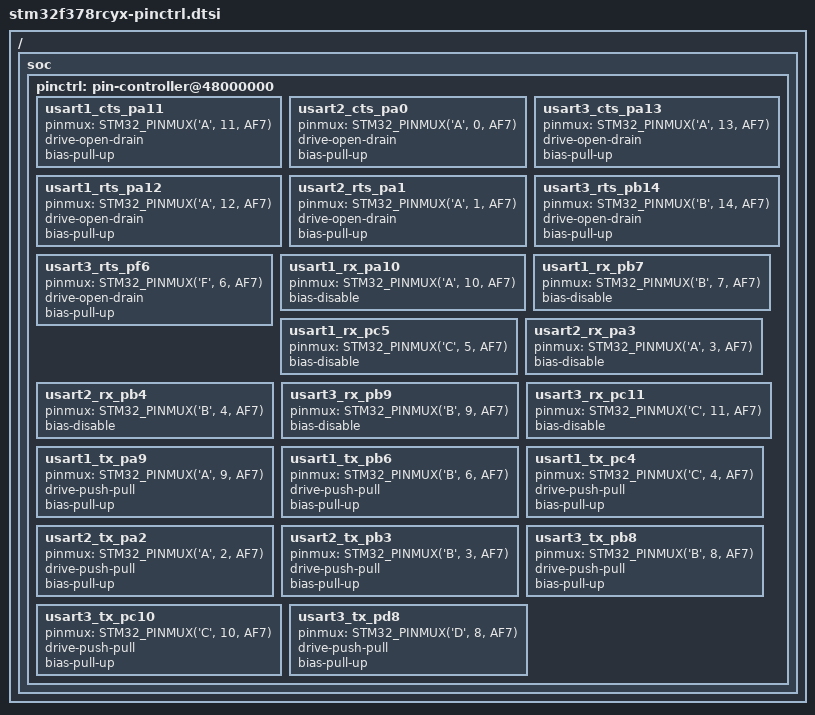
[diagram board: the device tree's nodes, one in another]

/*
 * NOTE: Autogenerated file using stm32_pinctrl_gen.py
 *
 * SPDX-License-Identifier: Apache-2.0
 */

#include <dt-bindings/pinctrl/stm32-pinctrl.h>

/ {
	soc {
		pinctrl: pin-controller@48000000 {
			/* UART_CTS */
			usart1_cts_pa11: usart1_cts_pa11 {
				pinmux = <STM32_PINMUX('A', 11, AF7)>;
				drive-open-drain;
				bias-pull-up;
			};

			usart2_cts_pa0: usart2_cts_pa0 {
				pinmux = <STM32_PINMUX('A', 0, AF7)>;
				drive-open-drain;
				bias-pull-up;
			};

			usart3_cts_pa13: usart3_cts_pa13 {
				pinmux = <STM32_PINMUX('A', 13, AF7)>;
				drive-open-drain;
				bias-pull-up;
			};


			/* UART_RTS */
			usart1_rts_pa12: usart1_rts_pa12 {
				pinmux = <STM32_PINMUX('A', 12, AF7)>;
				drive-open-drain;
				bias-pull-up;
			};

			usart2_rts_pa1: usart2_rts_pa1 {
				pinmux = <STM32_PINMUX('A', 1, AF7)>;
				drive-open-drain;
				bias-pull-up;
			};

			usart3_rts_pb14: usart3_rts_pb14 {
				pinmux = <STM32_PINMUX('B', 14, AF7)>;
				drive-open-drain;
				bias-pull-up;
			};

			usart3_rts_pf6: usart3_rts_pf6 {
				pinmux = <STM32_PINMUX('F', 6, AF7)>;
				drive-open-drain;
				bias-pull-up;
			};


			/* UART_RX */
			usart1_rx_pa10: usart1_rx_pa10 {
				pinmux = <STM32_PINMUX('A', 10, AF7)>;
				bias-disable;
			};

			usart1_rx_pb7: usart1_rx_pb7 {
				pinmux = <STM32_PINMUX('B', 7, AF7)>;
				bias-disable;
			};

			usart1_rx_pc5: usart1_rx_pc5 {
				pinmux = <STM32_PINMUX('C', 5, AF7)>;
				bias-disable;
			};

			usart2_rx_pa3: usart2_rx_pa3 {
				pinmux = <STM32_PINMUX('A', 3, AF7)>;
				bias-disable;
			};

			usart2_rx_pb4: usart2_rx_pb4 {
				pinmux = <STM32_PINMUX('B', 4, AF7)>;
				bias-disable;
			};

			usart3_rx_pb9: usart3_rx_pb9 {
				pinmux = <STM32_PINMUX('B', 9, AF7)>;
				bias-disable;
			};

			usart3_rx_pc11: usart3_rx_pc11 {
				pinmux = <STM32_PINMUX('C', 11, AF7)>;
				bias-disable;
			};


			/* UART_TX */
			usart1_tx_pa9: usart1_tx_pa9 {
				pinmux = <STM32_PINMUX('A', 9, AF7)>;
				drive-push-pull;
				bias-pull-up;
			};

			usart1_tx_pb6: usart1_tx_pb6 {
				pinmux = <STM32_PINMUX('B', 6, AF7)>;
				drive-push-pull;
				bias-pull-up;
			};

			usart1_tx_pc4: usart1_tx_pc4 {
				pinmux = <STM32_PINMUX('C', 4, AF7)>;
				drive-push-pull;
				bias-pull-up;
			};

			usart2_tx_pa2: usart2_tx_pa2 {
				pinmux = <STM32_PINMUX('A', 2, AF7)>;
				drive-push-pull;
				bias-pull-up;
			};

			usart2_tx_pb3: usart2_tx_pb3 {
				pinmux = <STM32_PINMUX('B', 3, AF7)>;
				drive-push-pull;
				bias-pull-up;
			};

			usart3_tx_pb8: usart3_tx_pb8 {
				pinmux = <STM32_PINMUX('B', 8, AF7)>;
				drive-push-pull;
				bias-pull-up;
			};

			usart3_tx_pc10: usart3_tx_pc10 {
				pinmux = <STM32_PINMUX('C', 10, AF7)>;
				drive-push-pull;
				bias-pull-up;
			};

			usart3_tx_pd8: usart3_tx_pd8 {
				pinmux = <STM32_PINMUX('D', 8, AF7)>;
				drive-push-pull;
				bias-pull-up;
			};

		};
	};
};
